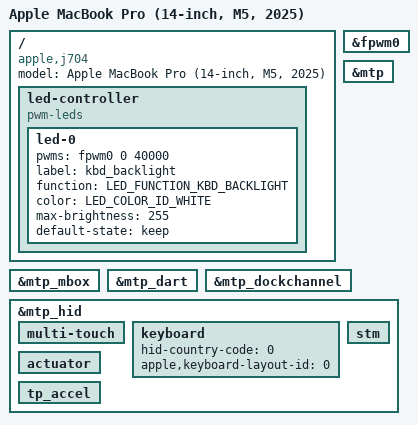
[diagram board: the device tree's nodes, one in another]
// SPDX-License-Identifier: GPL-2.0+ OR MIT
/*
 * Apple MacBook Pro (14-inch, M5, 2025)
 *
 * target-type: J704
 *
 * Copyright The Asahi Linux Contributors
 */

/dts-v1/;

#include "t8142.dtsi"
#include "t8142-jxxx.dtsi"
#include <dt-bindings/leds/common.h>

/ {
	compatible = "apple,j704", "apple,t8142", "apple,arm-platform";
	model = "Apple MacBook Pro (14-inch, M5, 2025)";

	led-controller {
		compatible = "pwm-leds";
		led-0 {
			pwms = <&fpwm0 0 40000>;
			label = "kbd_backlight";
			function = LED_FUNCTION_KBD_BACKLIGHT;
			color = <LED_COLOR_ID_WHITE>;
			max-brightness = <255>;
			default-state = "keep";
		};
	};
};

&fpwm0 {
	status = "okay";
};

&mtp {
	status = "okay";
};

&mtp_mbox {
	status = "okay";
};

&mtp_dart {
	status = "okay";
};

&mtp_dockchannel {
	status = "okay";
};

&mtp_hid {
	// apple,afe-reset-gpios = <&smc_gpio 8 GPIO_ACTIVE_LOW>;
	// apple,stm-reset-gpios = <&smc_gpio 24 GPIO_ACTIVE_LOW>;

	multi-touch {
	};

	keyboard: keyboard {
		hid-country-code = <0>;
		apple,keyboard-layout-id = <0>;
	};

	stm {
	};

	actuator {
	};

	tp_accel {
	};
};
